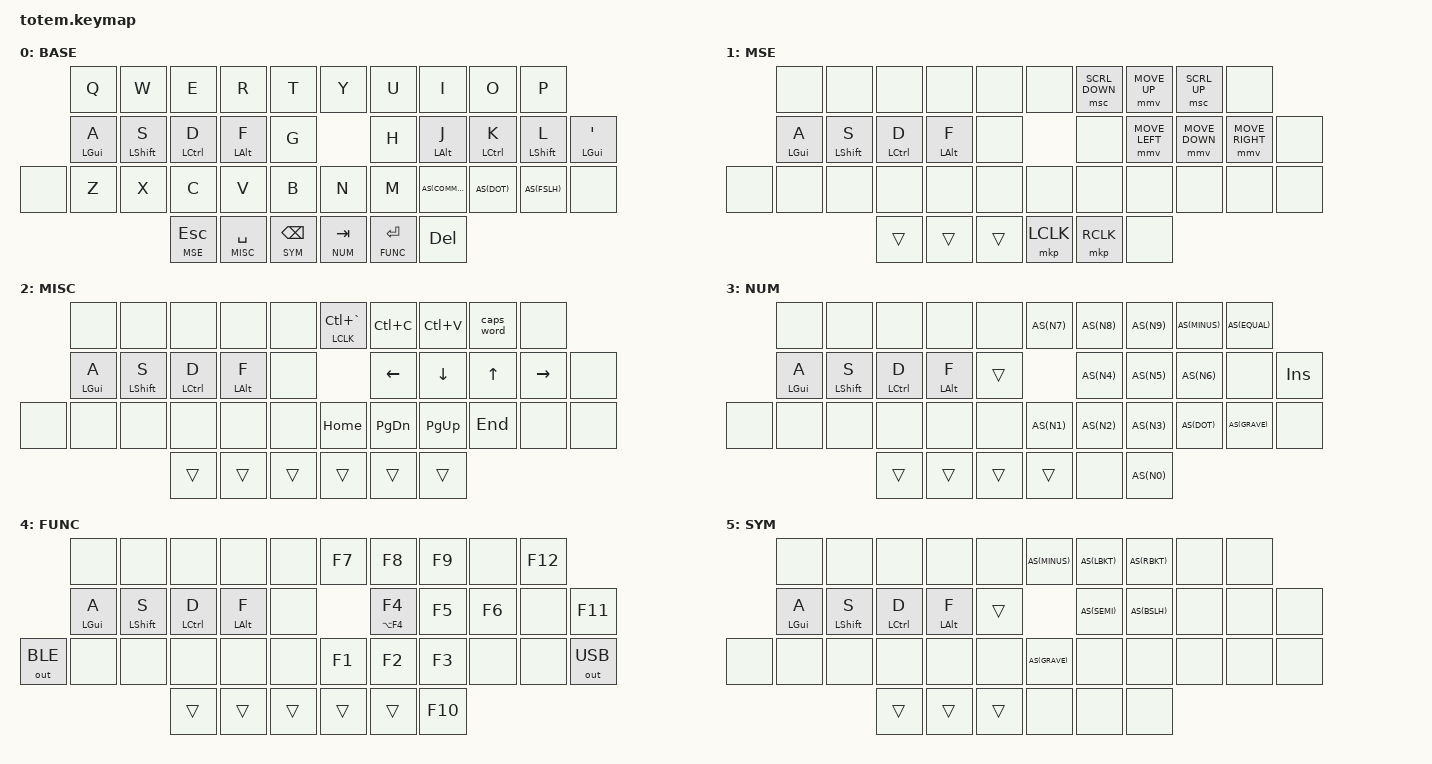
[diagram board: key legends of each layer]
//
//                                                        ▀▀▀▀▀     ▀▀▀▀▀          ▀▀█▀▀
//                                                        ▄▀▀▀▄  ▄  ▄▀▀▀▄  ▄  ▄▀▀▀▄  █  ▄▀▀▀▄
//                                                        █   █  █  █   █  █  █   █  █  █   █
//                                                         ▀▀▀   █   ▀▀▀   █   ▀▀▀   ▀   ▀▀▀
//                                                               █      ▄▄▄█▄▄▄    █   █  
//                                                               ▀      █  █  █     █▄█
//                                                             ▀▀▀▀▀    █  █  █      ▀
//                                                                      ▀  ▀  ▀
//
// ▄▄▄▄▄▄▄▄▄▄▄▄▄▄▄▄▄▄▄▄▄▄▄▄▄▄▄▄▄▄▄▄▄▄▄▄▄▄▄▄▄▄▄▄▄▄▄▄▄▄▄▄▄▄▄▄▄▄▄▄▄▄▄▄▄▄▄▄▄▄▄▄▄▄▄▄▄▄▄▄▄▄▄▄▄▄▄▄▄▄▄▄▄▄▄▄▄▄▄▄▄▄▄▄▄▄▄▄▄▄▄▄▄▄▄▄▄▄▄▄▄▄▄▄▄▄▄▄▄▄▄▄▄▄▄▄▄▄▄▄▄▄▄▄▄▄▄▄▄
       
#define ZMK_POINTING_DEFAULT_MOVE_VAL 800   // default: 600
#define ZMK_POINTING_DEFAULT_SCRL_VAL 20    // default: 10
#define AS(keycode) &as LS(keycode) keycode     // Autoshift Macro
#define MCLICK &mc_esc LCLK LC(GRAVE)

#include <dt-bindings/zmk/pointing.h>
//todo
// slow how quickly hold/autoshiftv happens


#include <behaviors.dtsi>
#include <dt-bindings/zmk/keys.h>
#include <dt-bindings/zmk/bt.h>
#include <dt-bindings/zmk/outputs.h>

#define BASE 0
#define MSE 1
#define MISC 2
#define NUM 3
#define FUNC 4
#define SYM 5

&mt {
  quick-tap-ms = <100>;
  global-quick-tap;
  flavor = "tap-preferred";
  tapping-term-ms = <220>;
};

&mmv {
    time-to-max-speed-ms = <55>;
    acceleration-exponent = <1>;
};

&lt {
    tapping-term-ms = <200>; // This is the value already set by default
};

/ {
    behaviors {
      as: auto_shift {
        compatible = "zmk,behavior-hold-tap";
        #binding-cells = <2>;
        tapping-term-ms = <250>;
        quick-tap-ms = <0>;
        flavor = "tap-preferred";
        bindings = <&kp>, <&kp>;
        };
      lt: layer_tap {
        compatible = "zmk,behavior-hold-tap";
        #binding-cells = <2>;
        flavor = "tap-preferred";
        tapping-term-ms = <250>;
        bindings = <&mo>, <&kp>;
        display-name = "Layer-Tap";
       };
      mc_esc: mouse_click_escape { // <--- Your new custom Hold-Tap behavior
        compatible = "zmk,behavior-hold-tap";
        #binding-cells = <2>;
        tapping-term-ms = <250>;
        quick-tap-ms = <0>;
        flavor = "tap-preferred";
        bindings = <&mkp>, <&kp>;
      };
      long_tap: long_tap_behavior {
        compatible = "zmk,behavior-hold-tap";
        #binding-cells = <2>;
        flavor = "tap-preferred";
        tapping-term-ms = <400>; // Custom duration for this key
        bindings = <&kp>, <&kp>;
        };
    };
        keymap {
                compatible = "zmk,keymap";
// ▄▄▄▄▄▄▄▄▄▄▄▄▄▄▄▄▄▄▄▄▄▄▄▄▄▄▄▄▄▄▄▄▄▄▄▄▄▄▄▄▄▄▄▄▄▄▄▄▄▄▄▄▄▄▄▄▄▄▄▄▄▄▄▄▄▄▄▄▄▄▄▄▄▄▄▄▄▄▄▄▄▄▄▄▄▄▄▄▄▄▄▄▄▄▄▄▄▄▄▄▄▄▄▄▄▄▄▄▄▄▄▄▄▄▄▄▄▄▄▄▄▄▄▄▄▄▄▄▄▄▄▄▄▄▄▄▄▄▄▄▄▄▄▄▄▄▄▄▄

                base_layer {
// ┏━━━━━━━━━━━━━━━━━━━━━━━━━━━━━━━━━━━━━━━┓
label= "BASE"                              ;
// ┗━━━━━━━━━━━━━━━━━━━━━━━━━━━━━━━━━━━━━━━┛
//             ┏━━━━━━━━━━━┳━━━━━━━━━━━┳━━━━━━━━━━━┳━━━━━━━━━━━┳━━━━━━━━━━━┓   ┏━━━━━━━━━━━┳━━━━━━━━━━━┳━━━━━━━━━━━┳━━━━━━━━━━━┳━━━━━━━━━━━┓
//             ┃     Q     ┃     W     ┃     E     ┃     R     ┃     T     ┃   ┃     Y     ┃     U     ┃     I     ┃     O     ┃     P     ┃
//             ┣━━━━━━━━━━━╋━━━━━━━━━━━╋━━━━━━━━━━━╋━━━━━━━━━━━╋━━━━━━━━━━━┫   ┣━━━━━━━━━━━╋━━━━━━━━━━━╋━━━━━━━━━━━╋━━━━━━━━━━━╋━━━━━━━━━━━┫
//             ┃     A     ┃     S     ┃     D     ┃     F     ┃     G     ┃   ┃     H     ┃     J     ┃     K     ┃     L     ┃     '     ┃
// ┏━━━━━━━━━━━╋━━━━━━━━━━━╋━━━━━━━━━━━╋━━━━━━━━━━━╋━━━━━━━━━━━╋━━━━━━━━━━━┫   ┣━━━━━━━━━━━╋━━━━━━━━━━━╋━━━━━━━━━━━╋━━━━━━━━━━━╋━━━━━━━━━━━╋━━━━━━━━━━━┓
// ┃    Z      ┃     Z     ┃     X     ┃     C     ┃     V     ┃     B     ┃   ┃     N     ┃     M     ┃     ,     ┃     .     ┃     /     ┃           ┃
// ┗━━━━━━━━━━━┻━━━━━━━━━━━┻━━━━━━━━━━━╋━━━━━━━━━━━╋━━━━━━━━━━━╋━━━━━━━━━━━┫   ┣━━━━━━━━━━━╋━━━━━━━━━━━╋━━━━━━━━━━━╋━━━━━━━━━━━┻━━━━━━━━━━━┻━━━━━━━━━━━┛
//                                     ┃    ESC    ┃    SPC    ┃    BSPC   ┃   ┃   TAB     ┃   ENTER   ┃    DEL    ┃
//                                     ┗━━━━━━━━━━━┻━━━━━━━━━━━┻━━━━━━━━━━━┛   ┗━━━━━━━━━━━┻━━━━━━━━━━━┻━━━━━━━━━━━┛
 bindings = <
// ╷           ╷           ╷           ╷           ╷           ╷           ╷   ╷           ╷           ╷           ╷           ╷           ╷           ╷

                &kp Q       &kp W       &kp E       &kp R       &kp T           &kp Y       &kp U       &kp I       &kp O       &kp P
                &long_tap LGUI A  &mt LSHFT S &mt LCTRL D &mt LALT F  &kp G           &kp H       &mt LALT J  &mt LCTRL K    &mt LSHFT L &long_tap LGUI QUOT
    &none       &kp Z       &kp X       &kp C       &kp V       &kp B           &kp N       &kp M       AS(COMMA)   AS(DOT)     AS(FSLH)    &none
                                        &lt MSE ESC &lt MISC SPACE &lt SYM BSPC &lt NUM TAB &lt FUNC RET &kp DEL
                        >;
                };
// ▄▄▄▄▄▄▄▄▄▄▄▄▄▄▄▄▄▄▄▄▄▄▄▄▄▄▄▄▄▄▄▄▄▄▄▄▄▄▄▄▄▄▄▄▄▄▄▄▄▄▄▄▄▄▄▄▄▄▄▄▄▄▄▄▄▄▄▄▄▄▄▄▄▄▄▄▄▄▄▄▄▄▄▄▄▄▄▄▄▄▄▄▄▄▄▄▄▄▄▄▄▄▄▄▄▄▄▄▄▄▄▄▄▄▄▄▄▄▄▄▄▄▄▄▄▄▄▄▄▄▄▄▄▄▄▄▄▄▄▄▄▄▄▄▄▄▄▄▄

                mouse_layer {
// ┏━━━━━━━━━━━━━━━━━━━━━━━━━━━━━━━━━━━━━━━┓
label= "MSE"                               ;
// ┗━━━━━━━━━━━━━━━━━━━━━━━━━━━━━━━━━━━━━━━┛
//             ┏━━━━━━━━━━━┳━━━━━━━━━━━┳━━━━━━━━━━━┳━━━━━━━━━━━┳━━━━━━━━━━━┓   ┏━━━━━━━━━━━┳━━━━━━━━━━━┳━━━━━━━━━━━┳━━━━━━━━━━━┳━━━━━━━━━━━┓
//             ┃           ┃           ┃           ┃           ┃           ┃   ┃           ┃ SCRL_DOWN ┃  MOVE_UP  ┃  SCRL_UP  ┃           ┃
//             ┣━━━━━━━━━━━╋━━━━━━━━━━━╋━━━━━━━━━━━╋━━━━━━━━━━━╋━━━━━━━━━━━┫   ┣━━━━━━━━━━━╋━━━━━━━━━━━╋━━━━━━━━━━━╋━━━━━━━━━━━╋━━━━━━━━━━━┫
//             ┃   LGUI    ┃   LSHFT   ┃   LCTRL   ┃   LALT    ┃           ┃   ┃           ┃ MOVE_LEFT ┃ MOVE_DOWN ┃ MOVE_RIGHT┃           ┃
// ┏━━━━━━━━━━━╋━━━━━━━━━━━╋━━━━━━━━━━━╋━━━━━━━━━━━╋━━━━━━━━━━━╋━━━━━━━━━━━┫   ┣━━━━━━━━━━━╋━━━━━━━━━━━╋━━━━━━━━━━━╋━━━━━━━━━━━╋━━━━━━━━━━━╋━━━━━━━━━━━┓
// ┃           ┃           ┃           ┃           ┃           ┃           ┃   ┃           ┃           ┃           ┃           ┃           ┃           ┃
// ┗━━━━━━━━━━━┻━━━━━━━━━━━┻━━━━━━━━━━━╋━━━━━━━━━━━╋━━━━━━━━━━━╋━━━━━━━━━━━┫   ┣━━━━━━━━━━━╋━━━━━━━━━━━╋━━━━━━━━━━━╋━━━━━━━━━━━┻━━━━━━━━━━━┻━━━━━━━━━━━┛
//                                     ┃           ┃           ┃           ┃   ┃   LCLK    ┃    RCLK   ┃           ┃
//                                     ┗━━━━━━━━━━━┻━━━━━━━━━━━┻━━━━━━━━━━━┛   ┗━━━━━━━━━━━┻━━━━━━━━━━━┻━━━━━━━━━━━┛
 bindings = <
// ╷           ╷           ╷           ╷           ╷           ╷           ╷   ╷           ╷           ╷           ╷           ╷           ╷           ╷

                &none       &none       &none       &none       &none           &none       &msc SCRL_DOWN &mmv MOVE_UP &msc SCRL_UP &none
                &mt LGUI A  &mt LSHFT S &mt LCTRL D &mt LALT F  &none           &none       &mmv MOVE_LEFT &mmv MOVE_DOWN &mmv MOVE_RIGHT &none
    &none       &none       &none       &none       &none       &none           &none       &none       &none       &none       &none       &none
                                        &trans      &trans       &trans           &mkp LCLK   &mkp RCLK   &none
                        >;
                };
// ▄▄▄▄▄▄▄▄▄▄▄▄▄▄▄▄▄▄▄▄▄▄▄▄▄▄▄▄▄▄▄▄▄▄▄▄▄▄▄▄▄▄▄▄▄▄▄▄▄▄▄▄▄▄▄▄▄▄▄▄▄▄▄▄▄▄▄▄▄▄▄▄▄▄▄▄▄▄▄▄▄▄▄▄▄▄▄▄▄▄▄▄▄▄▄▄▄▄▄▄▄▄▄▄▄▄▄▄▄▄▄▄▄▄▄▄▄▄▄▄▄▄▄▄▄▄▄▄▄▄▄▄▄▄▄▄▄▄▄▄▄▄▄▄▄▄▄▄▄

                misc_layer {
// ┏━━━━━━━━━━━━━━━━━━━━━━━━━━━━━━━━━━━━━━━┓
label= "MISC"                              ;
// ┗━━━━━━━━━━━━━━━━━━━━━━━━━━━━━━━━━━━━━━━┛
//             ┏━━━━━━━━━━━┳━━━━━━━━━━━┳━━━━━━━━━━━┳━━━━━━━━━━━┳━━━━━━━━━━━┓   ┏━━━━━━━━━━━┳━━━━━━━━━━━┳━━━━━━━━━━━┳━━━━━━━━━━━┳━━━━━━━━━━━┓
//             ┃           ┃           ┃           ┃           ┃           ┃   ┃  MCLICK   ┃    COPY   ┃   PASTE   ┃    CW     ┃           ┃
//             ┣━━━━━━━━━━━╋━━━━━━━━━━━╋━━━━━━━━━━━╋━━━━━━━━━━━╋━━━━━━━━━━━┫   ┣━━━━━━━━━━━╋━━━━━━━━━━━╋━━━━━━━━━━━╋━━━━━━━━━━━╋━━━━━━━━━━━┫
//             ┃   LGUI    ┃   LSHFT   ┃   LCTRL   ┃   LALT    ┃           ┃   ┃   LEFT    ┃    DOWN   ┃    UP     ┃   RIGHT   ┃           ┃
// ┏━━━━━━━━━━━╋━━━━━━━━━━━╋━━━━━━━━━━━╋━━━━━━━━━━━╋━━━━━━━━━━━╋━━━━━━━━━━━┫   ┣━━━━━━━━━━━╋━━━━━━━━━━━╋━━━━━━━━━━━╋━━━━━━━━━━━╋━━━━━━━━━━━╋━━━━━━━━━━━┓
// ┃           ┃           ┃           ┃           ┃           ┃           ┃   ┃   HOME    ┃   PG DN   ┃   PG UP   ┃    END    ┃           ┃           ┃
// ┗━━━━━━━━━━━┻━━━━━━━━━━━┻━━━━━━━━━━━╋━━━━━━━━━━━╋━━━━━━━━━━━╋━━━━━━━━━━━┫   ┣━━━━━━━━━━━╋━━━━━━━━━━━╋━━━━━━━━━━━╋━━━━━━━━━━━┻━━━━━━━━━━━┻━━━━━━━━━━━┛
//                                     ┃           ┃           ┃           ┃   ┃           ┃           ┃           ┃
//                                     ┗━━━━━━━━━━━┻━━━━━━━━━━━┻━━━━━━━━━━━┛   ┗━━━━━━━━━━━┻━━━━━━━━━━━┻━━━━━━━━━━━┛
 bindings = <
// ╷           ╷           ╷           ╷           ╷           ╷           ╷   ╷           ╷           ╷           ╷           ╷           ╷           ╷

                &none       &none       &none       &none       &none           MCLICK      &kp LC(C)   &kp LC(V)   &caps_word  &none
                &mt LGUI A  &mt LSHFT S &mt LCTRL D &mt LALT F  &none           &kp LEFT    &kp DOWN    &kp UP      &kp RIGHT   &none
    &none       &none       &none       &none       &none       &none           &kp HOME    &kp PG_DN   &kp PG_UP   &kp END     &none       &none
                                        &trans      &trans      &trans          &trans      &trans      &trans
                        >;
                };
// ▄▄▄▄▄▄▄▄▄▄▄▄▄▄▄▄▄▄▄▄▄▄▄▄▄▄▄▄▄▄▄▄▄▄▄▄▄▄▄▄▄▄▄▄▄▄▄▄▄▄▄▄▄▄▄▄▄▄▄▄▄▄▄▄▄▄▄▄▄▄▄▄▄▄▄▄▄▄▄▄▄▄▄▄▄▄▄▄▄▄▄▄▄▄▄▄▄▄▄▄▄▄▄▄▄▄▄▄▄▄▄▄▄▄▄▄▄▄▄▄▄▄▄▄▄▄▄▄▄▄▄▄▄▄▄▄▄▄▄▄▄▄▄▄▄▄▄▄▄
                num_layer {
// ┏━━━━━━━━━━━━━━━━━━━━━━━━━━━━━━━━━━━━━━━┓
label= "NUM"                               ;
// ┗━━━━━━━━━━━━━━━━━━━━━━━━━━━━━━━━━━━━━━━┛
//             ┏━━━━━━━━━━━┳━━━━━━━━━━━┳━━━━━━━━━━━┳━━━━━━━━━━━┳━━━━━━━━━━━┓   ┏━━━━━━━━━━━┳━━━━━━━━━━━┳━━━━━━━━━━━┳━━━━━━━━━━━┳━━━━━━━━━━━┓
//             ┃           ┃           ┃           ┃           ┃           ┃   ┃     7     ┃     8     ┃     9     ┃   MINUS   ┃    EQL    ┃
//             ┣━━━━━━━━━━━╋━━━━━━━━━━━╋━━━━━━━━━━━╋━━━━━━━━━━━╋━━━━━━━━━━━┫   ┣━━━━━━━━━━━╋━━━━━━━━━━━╋━━━━━━━━━━━╋━━━━━━━━━━━╋━━━━━━━━━━━┫
//             ┃   LGUI    ┃   LSHFT   ┃   LCTRL   ┃   LALT    ┃           ┃   ┃     4     ┃     5     ┃     6     ┃           ┃    INS    ┃
// ┏━━━━━━━━━━━╋━━━━━━━━━━━╋━━━━━━━━━━━╋━━━━━━━━━━━╋━━━━━━━━━━━╋━━━━━━━━━━━┫   ┣━━━━━━━━━━━╋━━━━━━━━━━━╋━━━━━━━━━━━╋━━━━━━━━━━━╋━━━━━━━━━━━╋━━━━━━━━━━━┓
// ┃           ┃           ┃           ┃           ┃           ┃           ┃   ┃     1     ┃     2     ┃     3     ┃    DOT    ┃    GRV    ┃           ┃
// ┗━━━━━━━━━━━┻━━━━━━━━━━━┻━━━━━━━━━━━╋━━━━━━━━━━━╋━━━━━━━━━━━╋━━━━━━━━━━━┫   ┣━━━━━━━━━━━╋━━━━━━━━━━━╋━━━━━━━━━━━╋━━━━━━━━━━━┻━━━━━━━━━━━┻━━━━━━━━━━━┛
//                                     ┃           ┃           ┃           ┃   ┃           ┃           ┃     0     ┃
//                                     ┗━━━━━━━━━━━┻━━━━━━━━━━━┻━━━━━━━━━━━┛   ┗━━━━━━━━━━━┻━━━━━━━━━━━┻━━━━━━━━━━━┛
 bindings = <
// ╷           ╷           ╷           ╷           ╷           ╷           ╷   ╷           ╷           ╷           ╷           ╷           ╷           ╷

                &none       &none       &none       &none       &none           AS(N7)      AS(N8)      AS(N9)      AS(MINUS)   AS(EQUAL)
                &mt LGUI A  &mt LSHFT S &mt LCTRL D &mt LALT F  &trans          AS(N4)      AS(N5)      AS(N6)      &none       &kp INS
    &none       &none       &none       &none       &none       &none           AS(N1)      AS(N2)      AS(N3)      AS(DOT)     AS(GRAVE)   &none
                                        &trans      &trans      &trans          &trans      &none       AS(N0)
                        >;
                };
// ▄▄▄▄▄▄▄▄▄▄▄▄▄▄▄▄▄▄▄▄▄▄▄▄▄▄▄▄▄▄▄▄▄▄▄▄▄▄▄▄▄▄▄▄▄▄▄▄▄▄▄▄▄▄▄▄▄▄▄▄▄▄▄▄▄▄▄▄▄▄▄▄▄▄▄▄▄▄▄▄▄▄▄▄▄▄▄▄▄▄▄▄▄▄▄▄▄▄▄▄▄▄▄▄▄▄▄▄▄▄▄▄▄▄▄▄▄▄▄▄▄▄▄▄▄▄▄▄▄▄▄▄▄▄▄▄▄▄▄▄▄▄▄▄▄▄▄▄▄
                func_layer {
// ┏━━━━━━━━━━━━━━━━━━━━━━━━━━━━━━━━━━━━━━━┓
label= "FUNC"                              ;
// ┗━━━━━━━━━━━━━━━━━━━━━━━━━━━━━━━━━━━━━━━┛
//             ┏━━━━━━━━━━━┳━━━━━━━━━━━┳━━━━━━━━━━━┳━━━━━━━━━━━┳━━━━━━━━━━━┓   ┏━━━━━━━━━━━┳━━━━━━━━━━━┳━━━━━━━━━━━┳━━━━━━━━━━━┳━━━━━━━━━━━┓
//             ┃           ┃           ┃           ┃           ┃           ┃   ┃     F7    ┃     F8    ┃     F9    ┃           ┃    F12    ┃
//             ┣━━━━━━━━━━━╋━━━━━━━━━━━╋━━━━━━━━━━━╋━━━━━━━━━━━╋━━━━━━━━━━━┫   ┣━━━━━━━━━━━╋━━━━━━━━━━━╋━━━━━━━━━━━╋━━━━━━━━━━━╋━━━━━━━━━━━┫
//             ┃   LGUI    ┃   LSHFT   ┃   LCTRL   ┃   LALT    ┃           ┃   ┃     F4    ┃     F5    ┃     F6    ┃           ┃    F11    ┃
// ┏━━━━━━━━━━━╋━━━━━━━━━━━╋━━━━━━━━━━━╋━━━━━━━━━━━╋━━━━━━━━━━━╋━━━━━━━━━━━┫   ┣━━━━━━━━━━━╋━━━━━━━━━━━╋━━━━━━━━━━━╋━━━━━━━━━━━╋━━━━━━━━━━━╋━━━━━━━━━━━┓
// ┃  BT TOGG  ┃           ┃           ┃           ┃           ┃           ┃   ┃     F1    ┃     F2    ┃     F3    ┃           ┃           ┃  USB TOGG ┃
// ┗━━━━━━━━━━━┻━━━━━━━━━━━┻━━━━━━━━━━━╋━━━━━━━━━━━╋━━━━━━━━━━━╋━━━━━━━━━━━┫   ┣━━━━━━━━━━━╋━━━━━━━━━━━╋━━━━━━━━━━━╋━━━━━━━━━━━┻━━━━━━━━━━━┻━━━━━━━━━━━┛
//                                     ┃           ┃           ┃           ┃   ┃           ┃           ┃     F10   ┃
//                                     ┗━━━━━━━━━━━┻━━━━━━━━━━━┻━━━━━━━━━━━┛   ┗━━━━━━━━━━━┻━━━━━━━━━━━┻━━━━━━━━━━━┛
 bindings = <
// ╷           ╷           ╷           ╷           ╷           ╷           ╷   ╷           ╷           ╷           ╷           ╷           ╷           ╷

                &none       &none       &none       &none       &none           &kp F7      &kp F8      &kp F9      &none       &kp F12
                &mt LGUI A  &mt LSHFT S &mt LCTRL D &mt LALT F  &none           &mt LA(F4) F4 &kp F5      &kp F6      &none       &kp F11
    &out OUT_BLE &none       &none       &none       &none      &none           &kp F1      &kp F2      &kp F3      &none       &none       &out OUT_USB
                                         &trans      &trans     &trans          &trans      &trans      &kp F10
                        >;
                };
// ▄▄▄▄▄▄▄▄▄▄▄▄▄▄▄▄▄▄▄▄▄▄▄▄▄▄▄▄▄▄▄▄▄▄▄▄▄▄▄▄▄▄▄▄▄▄▄▄▄▄▄▄▄▄▄▄▄▄▄▄▄▄▄▄▄▄▄▄▄▄▄▄▄▄▄▄▄▄▄▄▄▄▄▄▄▄▄▄▄▄▄▄▄▄▄▄▄▄▄▄▄▄▄▄▄▄▄▄▄▄▄▄▄▄▄▄▄▄▄▄▄▄▄▄▄▄▄▄▄▄▄▄▄▄▄▄▄▄▄▄▄▄▄▄▄▄▄▄▄
                sym_layer {
// ┏━━━━━━━━━━━━━━━━━━━━━━━━━━━━━━━━━━━━━━━┓
label= "SYM"                               ;
// ┗━━━━━━━━━━━━━━━━━━━━━━━━━━━━━━━━━━━━━━━┛
//             ┏━━━━━━━━━━━┳━━━━━━━━━━━┳━━━━━━━━━━━┳━━━━━━━━━━━┳━━━━━━━━━━━┓   ┏━━━━━━━━━━━┳━━━━━━━━━━━┳━━━━━━━━━━━┳━━━━━━━━━━━┳━━━━━━━━━━━┓
//             ┃           ┃           ┃           ┃           ┃           ┃   ┃     -     ┃     [     ┃     ]     ┃           ┃           ┃
//             ┣━━━━━━━━━━━╋━━━━━━━━━━━╋━━━━━━━━━━━╋━━━━━━━━━━━╋━━━━━━━━━━━┫   ┣━━━━━━━━━━━╋━━━━━━━━━━━╋━━━━━━━━━━━╋━━━━━━━━━━━╋━━━━━━━━━━━┫
//             ┃   LGUI    ┃   LSHFT   ┃   LCTRL   ┃   LALT    ┃           ┃   ┃     ;     ┃     \     ┃           ┃           ┃           ┃
// ┏━━━━━━━━━━━╋━━━━━━━━━━━╋━━━━━━━━━━━╋━━━━━━━━━━━╋━━━━━━━━━━━╋━━━━━━━━━━━┫   ┣━━━━━━━━━━━╋━━━━━━━━━━━╋━━━━━━━━━━━╋━━━━━━━━━━━╋━━━━━━━━━━━╋━━━━━━━━━━━┓
// ┃           ┃           ┃           ┃           ┃           ┃           ┃   ┃     `     ┃           ┃           ┃           ┃           ┃           ┃
// ┗━━━━━━━━━━━┻━━━━━━━━━━━┻━━━━━━━━━━━╋━━━━━━━━━━━╋━━━━━━━━━━━╋━━━━━━━━━━━┫   ┣━━━━━━━━━━━╋━━━━━━━━━━━╋━━━━━━━━━━━╋━━━━━━━━━━━┻━━━━━━━━━━━┻━━━━━━━━━━━┛
//                                     ┃           ┃           ┃           ┃   ┃           ┃           ┃           ┃
//                                     ┗━━━━━━━━━━━┻━━━━━━━━━━━┻━━━━━━━━━━━┛   ┗━━━━━━━━━━━┻━━━━━━━━━━━┻━━━━━━━━━━━┛
 bindings = <
// ╷           ╷           ╷           ╷           ╷           ╷           ╷   ╷           ╷           ╷           ╷           ╷           ╷           ╷

                &none       &none       &none       &none       &none           AS(MINUS)   AS(LBKT)    AS(RBKT)    &none       &none
                &mt LGUI A  &mt LSHFT S &mt LCTRL D &mt LALT F  &trans          AS(SEMI)    AS(BSLH)    &none       &none       &none
    &none       &none       &none       &none       &none       &none           AS(GRAVE)   &none       &none       &none       &none       &none
                                            &trans      &trans        &trans          &none       &none       &none
                        >;
                };
        };
};
